# f2838x_cm_gcrc_regs register map
Vendor: Texas Instruments
Peripheral module from a debugger description file (folder C2000).
Address unit: 16 bits
Registers are 32-bit, read-write, no defined reset value unless marked. A register's access mark holds for its fields unless they carry their own. Offsets are as the file gives them; lines under a group give offsets from that group; [hi:lo] are bit positions; {n}, {i} and the like mark numbered series; 'fields as' and 'values as' point back to an identical list; <NAME> marks a mode.

## GCRC_REGS — GCRC Registers
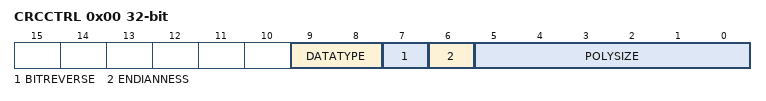
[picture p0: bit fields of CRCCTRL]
0x00 CRCCTRL — CRC Control Register
  [9:8] DATATYPE — Defines the DATATYPE of the element of the data array.
  [7] BITREVERSE — Enables the DATAIN bus to the CRC engine to be bit reversed.
  [6] ENDIANNESS — Defines the endianness of the data stream.
  [5:0] POLYSIZE — CRC polynomial order
0x04 CRCPOLY — CRC Polynomial Register
  [31:0] POLY — CRC polynomial
0x08 CRCDATAMASK
  [4:0] DATAMASK — Number of bits to be masked
0x0C CRCDATAIN — CRC Data Input Register
  [31:0] DATAIN — CRC data input
0x10 CRCDATAOUT — CRC Data Output Register
  [31:0] DATA — CRC DATAOUT
0x14 CRCDATATRANS ro — CRC Transformed Data Register
  [31:0] DATAIN — Transformed data
